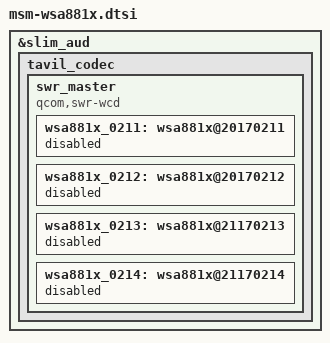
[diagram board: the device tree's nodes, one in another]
// SPDX-License-Identifier: GPL-2.0-only
/*
 * Copyright (c) 2016-2017, The Linux Foundation. All rights reserved.
 */

&slim_aud {
	tavil_codec {
		swr_master {
			compatible = "qcom,swr-wcd";
			#address-cells = <2>;
			#size-cells = <0>;

			wsa881x_0211: wsa881x@20170211 {
				status = "disabled";
			};

			wsa881x_0212: wsa881x@20170212 {
				status = "disabled";
			};

			wsa881x_0213: wsa881x@21170213 {
				status = "disabled";
			};

			wsa881x_0214: wsa881x@21170214 {
				status = "disabled";
			};
		};
	};
};
